# CM41x_M4 register map
Vendor: Analog Devices; Series: CM41x_M4; File version: 1p0
CPU: CM4 r0p1, little endian, MPU, FPU, 4 interrupt priority bits
Registers are 32-bit, read-write, reset 0x0 unless marked. A register's access mark holds for its fields unless they carry their own. Offsets are from the block's base; [hi:lo] are bit positions; lines under a group give offsets from that group; {n}, {i} and the like mark numbered series.

## TRU1 — Trigger Routing Unit
Base 0x40020000
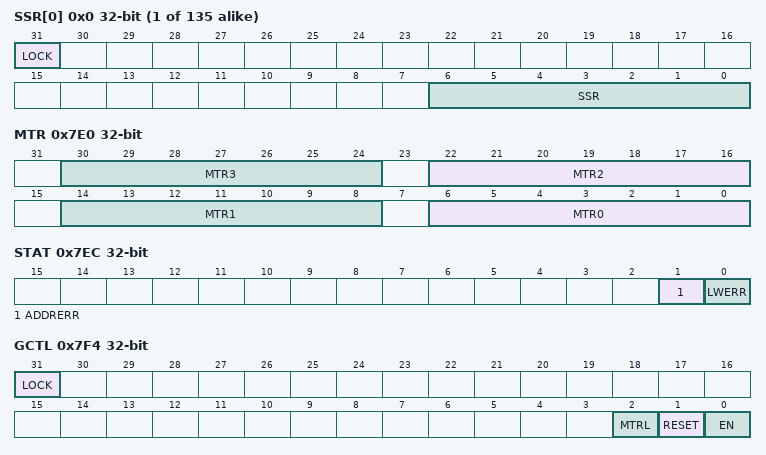
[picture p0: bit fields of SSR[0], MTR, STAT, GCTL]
{0x0+4i} SSR[{i}] (i=0..134) — Slave Select Register
  [31] LOCK — SSRn Lock
  [6:0] SSR — SSRn Slave Select
0x7E0 MTR — Master Trigger Register
  [8n+6:8n] MTR{n} (n=0..3) — Master Trigger Register {n}
0x7E8 ERRADDR — Error Address Register
  [11:0] ADDR range 0x00000000..0x00000FFF — Error Address
0x7EC STAT — Status Information Register
  [1] ADDRERR — Address Error Status
  [0] LWERR — Lock Write Error Status
0x7F4 GCTL — Global Control Register
  [31] LOCK — GCTL Lock Bit
  [2] MTRL — MTR Lock Bit
  [1] RESET — Soft Reset
  [0] EN — Non-MMR Enable

## TRU0 — Trigger Routing Unit
Base 0x41006000
Registers as TRU1, without SSR[*]; these are added or differ:
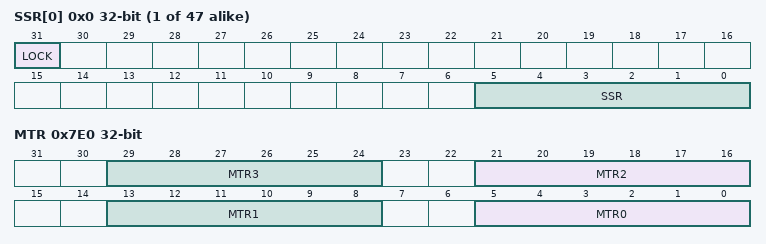
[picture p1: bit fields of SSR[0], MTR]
{0x0+4i} SSR[{i}] (i=0..46) — Slave Select Register
  [31] LOCK — SSRn Lock
  [5:0] SSR — SSRn Slave Select
0x7E0 MTR — Master Trigger Register
  [8n+5:8n] MTR{n} (n=0..3) — Master Trigger Register {n}

## CPTMR0 — Capture Timer
Base 0x40025000
0x04 RUN
  [2:0] CPTnn range 0x00000000..0x00000007 — Run
0x08 RUN_SET
  [2:0] CPTnn range 0x00000000..0x00000007 — Run
0x0C RUN_CLR — Run Clear Register
  [2:0] CPTnn range 0x00000000..0x00000007 — Run
0x10 DATA_IMSK reset 0x7 — Data Interrupt Mask Register
  [2:0] CPTnn range 0x00000000..0x00000007 — Data Interrupt Mask
0x14 DATA_IMSK_SET reset 0x7 — Data Interrupt Mask Set Register
  [2:0] CPTnn range 0x00000000..0x00000007 — Data Interrupt Mask
0x18 DATA_IMSK_CLR reset 0x7 — Data Interrupt Mask Clear Register
  [2:0] CPTnn range 0x00000000..0x00000007 — Data Interrupt Mask
0x1C STAT_IMSK reset 0x7 — Status Interrupt Mask Register
  [2:0] CPTnn range 0x00000000..0x00000007 — Status Interrupt Mask
0x20 STAT_IMSK_SET reset 0x7 — Status Interrupt Mask Set Register
  [2:0] CPTnn range 0x00000000..0x00000007 — Status Interrupt Mask
0x24 STAT_IMSK_CLR reset 0x7 — Status Interrupt Mask Clear Register
  [2:0] CPTnn range 0x00000000..0x00000007 — Status Interrupt Mask
0x28 DATA_ILAT — Data Interrupt Latch Status Register
  [2:0] CPTnn ro — Data Interrupt Latch
0x2C STAT_ILAT — Interrupt Latch Status Register
  [2:0] CPTnn ro — Counter Overflow
{0x800+0x80*i} CT[{i}] (i=0..2) group — Capture Timer
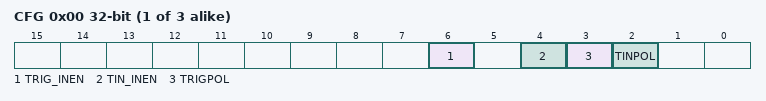
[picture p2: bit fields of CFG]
  0x00 CFG — Configuration Register
    [6] TRIG_INEN range 0x00000000..0x00000001 — Trigger Input Enable
    [4] TIN_INEN range 0x00000000..0x00000001 — Timer Input Enable
    [3] TRIGPOL range 0x00000000..0x00000001 — Trigger Polarity
    [2] TINPOL range 0x00000000..0x00000001 — Input Polarity
  0x04 CNT reset 0x1 — Counter Register
    [31:0] VALUE ro — Counter Value
  0x08 TON — On-time Capture Register
    [31:0] VALUE ro — On-time Value

## TTU0 — Trigger Timing Unit
Base 0x4002C000
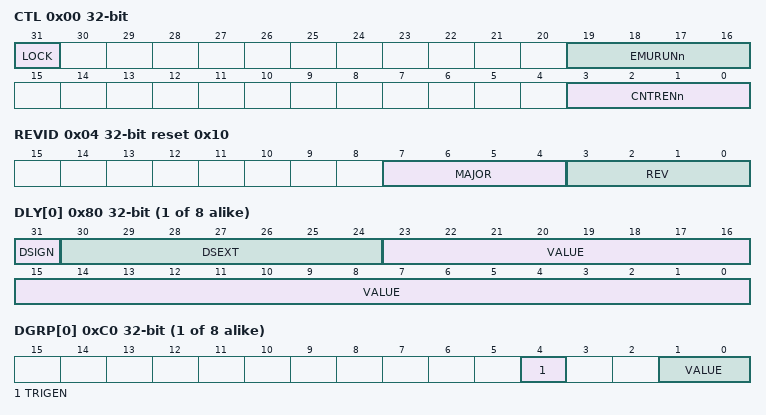
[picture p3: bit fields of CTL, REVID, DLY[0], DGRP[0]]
0x00 CTL — TTU Control Register
  [31] LOCK — Configuration Lock Bit
  [19:16] EMURUNn — Debug Emulation Run Mode
  [3:0] CNTRENn — Enable Counter n
0x04 REVID reset 0x10 — Revision ID Register
  [7:4] MAJOR ro — Major Revision Level
  [3:0] REV ro — Minor Revision Level
0x08 STOP — Counter Stop Request Register
  [3:0] STOPREQn range 0x00000000..0x0000000F — Stop Counter Request
0x0C STAT — Counter Status Register
  [3:0] RUNn ro — Counter Running Status
0x10 CHK — Counter Check Register
  [23:0] VALUE range 0x00000000..0x00FFFFFF — Counter Check
{0x20+4i} CNT[{i}] (i=0..3) — Counter Current Value
  [23:0] VALUE ro — Trigger Counter Value
{0x40+4i} PER[{i}] (i=0..3) — Counter Period Register
  [23:0] VALUE range 0x00000000..0x00FFFFFF — Counter Period
{0x80+4i} DLY[{i}] (i=0..7) — Trigger Output Delay Register
  [31] DSIGN range 0x00000000..0x00000001 — Trigger Output Delay Sign
  [30:24] DSEXT ro — Trigger Output Sign Extension
  [23:0] VALUE range 0x00000000..0x00FFFFFF — Trigger Output Delay
{0xC0+4i} DGRP[{i}] (i=0..7) — Trigger Output Counter Assignment
  [4] TRIGEN range 0x00000000..0x00000001 — Enable Trigger Output
  [1:0] VALUE range 0x00000000..0x00000003 — Trigger Output Counter Assignment
